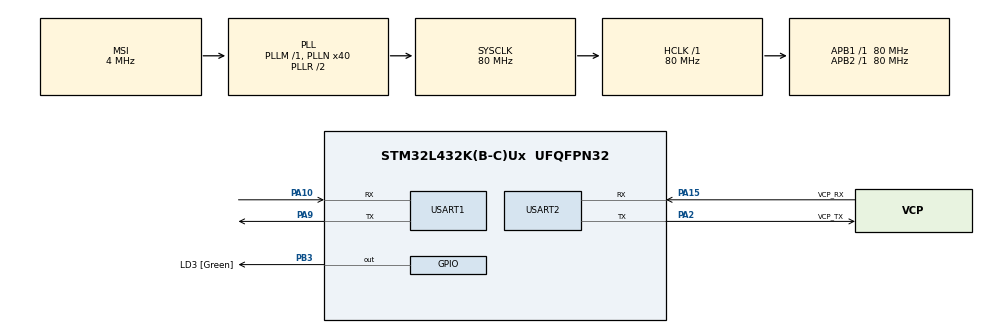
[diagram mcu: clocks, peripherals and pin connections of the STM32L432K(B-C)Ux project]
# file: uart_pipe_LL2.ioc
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Dma.Request0=USART1_RX
Dma.Request1=USART2_RX
Dma.USART1_RX.0.Direction=DMA_PERIPH_TO_MEMORY
Dma.USART1_RX.0.Instance=DMA1_Channel5
Dma.USART1_RX.0.MemDataAlignment=DMA_MDATAALIGN_BYTE
Dma.USART1_RX.0.MemInc=DMA_MINC_ENABLE
Dma.USART1_RX.0.Mode=DMA_NORMAL
Dma.USART1_RX.0.PeriphDataAlignment=DMA_PDATAALIGN_BYTE
Dma.USART1_RX.0.PeriphInc=DMA_PINC_DISABLE
Dma.USART1_RX.0.Priority=DMA_PRIORITY_HIGH
Dma.USART2_RX.1.Direction=DMA_PERIPH_TO_MEMORY
Dma.USART2_RX.1.Instance=DMA1_Channel6
Dma.USART2_RX.1.MemDataAlignment=DMA_MDATAALIGN_BYTE
Dma.USART2_RX.1.MemInc=DMA_MINC_ENABLE
Dma.USART2_RX.1.Mode=DMA_CIRCULAR
Dma.USART2_RX.1.PeriphDataAlignment=DMA_PDATAALIGN_BYTE
Dma.USART2_RX.1.PeriphInc=DMA_PINC_DISABLE
Dma.USART2_RX.1.Priority=DMA_PRIORITY_HIGH
Mcu.Family=STM32L4
Mcu.Name=STM32L432K(B-C)Ux
Mcu.Package=UFQFPN32
NVIC.DMA1_Channel5_IRQn=true\:0\:0\:false\:false\:true
NVIC.DMA1_Channel6_IRQn=true\:0\:0\:false\:false\:true
NVIC.PriorityGroup=NVIC_PRIORITYGROUP_4
NVIC.USART1_IRQn=true\:0\:0\:false\:false\:true
NVIC.USART2_IRQn=true\:0\:0\:true\:false\:true
PA0-CK_IN.GPIO_Label=MCO [High speed clock in]
PA0-CK_IN.Signal=RCC_CK_IN
PA10.Mode=Asynchronous
PA10.Signal=USART1_RX
PA13\ (JTMS-SWDIO).GPIO_Label=SWDIO
PA13\ (JTMS-SWDIO).Signal=SYS_JTMS-SWDIO
PA14\ (JTCK-SWCLK).GPIO_Label=SWCLK
PA14\ (JTCK-SWCLK).Signal=SYS_JTCK-SWCLK
PA15\ (JTDI).GPIO_Label=VCP_RX
PA15\ (JTDI).Mode=Asynchronous
PA15\ (JTDI).Signal=USART2_RX
PA2.GPIO_Label=VCP_TX
PA2.Mode=Asynchronous
PA2.Signal=USART2_TX
PA9.Mode=Asynchronous
PA9.Signal=USART1_TX
PB3\ (JTDO-TRACESWO).GPIO_Label=LD3 [Green]
PB3\ (JTDO-TRACESWO).Signal=GPIO_Output
PC14-OSC32_IN\ (PC14).Signal=RCC_OSC32_IN
PC15-OSC32_OUT\ (PC15).Signal=RCC_OSC32_OUT
ProjectManager.HeapSize=0x200
ProjectManager.StackSize=0x400
ProjectManager.TargetToolchain=SW4STM32
RCC.AHBFreq_Value=80000000
RCC.APB1Freq_Value=80000000
RCC.APB1TimFreq_Value=80000000
RCC.APB2Freq_Value=80000000
RCC.APB2TimFreq_Value=80000000
RCC.CortexFreq_Value=80000000
RCC.HCLKFreq_Value=80000000
RCC.HSE_VALUE=8000000
RCC.HSI16_VALUE=16000000
RCC.HSI48_VALUE=48000000
RCC.HSI_VALUE=16000000
RCC.LSE_VALUE=32768
RCC.MSI_VALUE=4000000
RCC.PLLMUL=RCC_PLLMUL_4
RCC.PLLN=40
RCC.SYSCLKFreq_VALUE=80000000
RCC.SYSCLKSource=RCC_SYSCLKSOURCE_PLLCLK
RCC.VCOOutputFreq_Value=160000000
USART1.WordLength=UART_WORDLENGTH_8B
USART2.WordLength=UART_WORDLENGTH_8B
board=NUCLEO-L432KC

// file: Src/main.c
/**
  ******************************************************************************
  * File Name          : main.c
  * Description        : Main program body
  ******************************************************************************
  *
  * COPYRIGHT(c) 2016 STMicroelectronics
  *
  * Redistribution and use in source and binary forms, with or without modification,
  * are permitted provided that the following conditions are met:
  *   1. Redistributions of source code must retain the above copyright notice,
  *      this list of conditions and the following disclaimer.
  *   2. Redistributions in binary form must reproduce the above copyright notice,
  *      this list of conditions and the following disclaimer in the documentation
  *      and/or other materials provided with the distribution.
  *   3. Neither the name of STMicroelectronics nor the names of its contributors
  *      may be used to endorse or promote products derived from this software
  *      without specific prior written permission.
  *
  * THIS SOFTWARE IS PROVIDED BY THE COPYRIGHT HOLDERS AND CONTRIBUTORS "AS IS"
  * AND ANY EXPRESS OR IMPLIED WARRANTIES, INCLUDING, BUT NOT LIMITED TO, THE
  * IMPLIED WARRANTIES OF MERCHANTABILITY AND FITNESS FOR A PARTICULAR PURPOSE ARE
  * DISCLAIMED. IN NO EVENT SHALL THE COPYRIGHT HOLDER OR CONTRIBUTORS BE LIABLE
  * FOR ANY DIRECT, INDIRECT, INCIDENTAL, SPECIAL, EXEMPLARY, OR CONSEQUENTIAL
  * DAMAGES (INCLUDING, BUT NOT LIMITED TO, PROCUREMENT OF SUBSTITUTE GOODS OR
  * SERVICES; LOSS OF USE, DATA, OR PROFITS; OR BUSINESS INTERRUPTION) HOWEVER
  * CAUSED AND ON ANY THEORY OF LIABILITY, WHETHER IN CONTRACT, STRICT LIABILITY,
  * OR TORT (INCLUDING NEGLIGENCE OR OTHERWISE) ARISING IN ANY WAY OUT OF THE USE
  * OF THIS SOFTWARE, EVEN IF ADVISED OF THE POSSIBILITY OF SUCH DAMAGE.
  *
  ******************************************************************************
  */
#include "main.h"
#include "stm32l4xx_hal.h"

/* USER CODE BEGIN Includes */

#include "serial.h"

/* USER CODE END Includes */

UART_HandleTypeDef huart1;
UART_HandleTypeDef huart2;
DMA_HandleTypeDef hdma_usart1_rx;
DMA_HandleTypeDef hdma_usart2_rx;

/* USER CODE BEGIN PV */
/* Private variables ---------------------------------------------------------*/

//UARTSerial_t Serial2;

/* USER CODE END PV */

void SystemClock_Config(void);
void Error_Handler(void);
static void MX_GPIO_Init(void);
static void MX_DMA_Init(void);
static void MX_USART1_UART_Init(void);
static void MX_USART2_UART_Init(void);

/* USER CODE BEGIN PFP */
/* Private function prototypes -----------------------------------------------*/

/* USER CODE END PFP */

int main(void)
{

  /* MCU Configuration----------------------------------------------------------*/

  /* Reset of all peripherals, Initializes the Flash interface and the Systick. */
  HAL_Init();

  /* Configure the system clock */
  SystemClock_Config();

  /* Initialize all configured peripherals */
  MX_GPIO_Init();
  MX_DMA_Init();
  MX_USART1_UART_Init();
  MX_USART2_UART_Init();

  /* USER CODE BEGIN 2 */

  Serial2_begin();

  /* USER CODE END 2 */

  /* Infinite loop */
  while (1)
  {
//	  if(Serial2_available()){
//		  Serial2_write(Serial2_read());
//	  }

	  if(Serial2_available()){
		  uint8_t lol[32]; //the buffer required for reading multiple bytes
		  int l = Serial2_readCommand(lol); //returns length of command
		  if(l>0){
			  //below check only needed if you're not sure if the bus will be free.
			  //use in a for loop for timeout, i guess. Should clear fast at 115200B/s.
			  while(Serial2_availableForWrite()==0);
			  Serial2_writeBytes(lol, l);
		  }
	  }

//	  if(Serial2_available()==2){
//		  uint8_t lol[2];
//		  Serial2_readBytes(lol,2);
//		  while(Serial2_availableForWrite()==0);
//		  Serial2_writeBytes(lol,2);
//	  }
  }

}

/** System Clock Configuration
*/
void SystemClock_Config(void)
{

  RCC_OscInitTypeDef RCC_OscInitStruct;
  RCC_ClkInitTypeDef RCC_ClkInitStruct;
  RCC_PeriphCLKInitTypeDef PeriphClkInit;

    /**Initializes the CPU, AHB and APB busses clocks
    */
  RCC_OscInitStruct.OscillatorType = RCC_OSCILLATORTYPE_MSI;
  RCC_OscInitStruct.MSIState = RCC_MSI_ON;
  RCC_OscInitStruct.MSICalibrationValue = 0;
  RCC_OscInitStruct.MSIClockRange = RCC_MSIRANGE_6;
  RCC_OscInitStruct.PLL.PLLState = RCC_PLL_ON;
  RCC_OscInitStruct.PLL.PLLSource = RCC_PLLSOURCE_MSI;
  RCC_OscInitStruct.PLL.PLLM = 1;
  RCC_OscInitStruct.PLL.PLLN = 40;
  RCC_OscInitStruct.PLL.PLLP = RCC_PLLP_DIV7;
  RCC_OscInitStruct.PLL.PLLQ = RCC_PLLQ_DIV2;
  RCC_OscInitStruct.PLL.PLLR = RCC_PLLR_DIV2;
  if (HAL_RCC_OscConfig(&RCC_OscInitStruct) != HAL_OK)
  {
    Error_Handler();
  }

    /**Initializes the CPU, AHB and APB busses clocks
    */
  RCC_ClkInitStruct.ClockType = RCC_CLOCKTYPE_HCLK|RCC_CLOCKTYPE_SYSCLK
                              |RCC_CLOCKTYPE_PCLK1|RCC_CLOCKTYPE_PCLK2;
  RCC_ClkInitStruct.SYSCLKSource = RCC_SYSCLKSOURCE_PLLCLK;
  RCC_ClkInitStruct.AHBCLKDivider = RCC_SYSCLK_DIV1;
  RCC_ClkInitStruct.APB1CLKDivider = RCC_HCLK_DIV1;
  RCC_ClkInitStruct.APB2CLKDivider = RCC_HCLK_DIV1;

  if (HAL_RCC_ClockConfig(&RCC_ClkInitStruct, FLASH_LATENCY_4) != HAL_OK)
  {
    Error_Handler();
  }

  PeriphClkInit.PeriphClockSelection = RCC_PERIPHCLK_USART1|RCC_PERIPHCLK_USART2;
  PeriphClkInit.Usart1ClockSelection = RCC_USART1CLKSOURCE_PCLK2;
  PeriphClkInit.Usart2ClockSelection = RCC_USART2CLKSOURCE_PCLK1;
  if (HAL_RCCEx_PeriphCLKConfig(&PeriphClkInit) != HAL_OK)
  {
    Error_Handler();
  }

    /**Configure the main internal regulator output voltage
    */
  if (HAL_PWREx_ControlVoltageScaling(PWR_REGULATOR_VOLTAGE_SCALE1) != HAL_OK)
  {
    Error_Handler();
  }

    /**Configure the Systick interrupt time
    */
  HAL_SYSTICK_Config(HAL_RCC_GetHCLKFreq()/1000);

    /**Configure the Systick
    */
  HAL_SYSTICK_CLKSourceConfig(SYSTICK_CLKSOURCE_HCLK);

  /* SysTick_IRQn interrupt configuration */
  HAL_NVIC_SetPriority(SysTick_IRQn, 0, 0);
}

/* USART1 init function */
static void MX_USART1_UART_Init(void)
{

  huart1.Instance = USART1;
  huart1.Init.BaudRate = 115200;
  huart1.Init.WordLength = UART_WORDLENGTH_8B;
  huart1.Init.StopBits = UART_STOPBITS_1;
  huart1.Init.Parity = UART_PARITY_NONE;
  huart1.Init.Mode = UART_MODE_TX_RX;
  huart1.Init.HwFlowCtl = UART_HWCONTROL_NONE;
  huart1.Init.OverSampling = UART_OVERSAMPLING_16;
  huart1.Init.OneBitSampling = UART_ONE_BIT_SAMPLE_DISABLE;
  huart1.AdvancedInit.AdvFeatureInit = UART_ADVFEATURE_NO_INIT;
  if (HAL_UART_Init(&huart1) != HAL_OK)
  {
    Error_Handler();
  }

}

/* USART2 init function */
static void MX_USART2_UART_Init(void)
{

  huart2.Instance = USART2;
  huart2.Init.BaudRate = 115200;
  huart2.Init.WordLength = UART_WORDLENGTH_8B;
  huart2.Init.StopBits = UART_STOPBITS_1;
  huart2.Init.Parity = UART_PARITY_NONE;
  huart2.Init.Mode = UART_MODE_TX_RX;
  huart2.Init.HwFlowCtl = UART_HWCONTROL_NONE;
  huart2.Init.OverSampling = UART_OVERSAMPLING_16;
  huart2.Init.OneBitSampling = UART_ONE_BIT_SAMPLE_DISABLE;
  huart2.AdvancedInit.AdvFeatureInit = UART_ADVFEATURE_NO_INIT;
  if (HAL_UART_Init(&huart2) != HAL_OK)
  {
    Error_Handler();
  }

}

static void MX_DMA_Init(void)
{
  /* DMA controller clock enable */
  LL_AHB1_GRP1_EnableClock(LL_AHB1_GRP1_PERIPH_DMA1);

  /* DMA interrupt init */
  /* DMA1_Channel5_IRQn interrupt configuration */
  HAL_NVIC_SetPriority(DMA1_Channel5_IRQn, 0, 0);
  HAL_NVIC_EnableIRQ(DMA1_Channel5_IRQn);
  /* DMA1_Channel6_IRQn interrupt configuration */
  HAL_NVIC_SetPriority(DMA1_Channel6_IRQn, 0, 0);
  HAL_NVIC_EnableIRQ(DMA1_Channel6_IRQn);

}

/** Configure pins as
        * Analog
        * Input
        * Output
        * EVENT_OUT
        * EXTI
*/
static void MX_GPIO_Init(void)
{

  GPIO_InitTypeDef GPIO_InitStruct;

  /* GPIO Ports Clock Enable */
  __HAL_RCC_GPIOC_CLK_ENABLE();
  __HAL_RCC_GPIOA_CLK_ENABLE();
  __HAL_RCC_GPIOB_CLK_ENABLE();

  /*Configure GPIO pin Output Level */
  HAL_GPIO_WritePin(LD3_GPIO_Port, LD3_Pin, GPIO_PIN_RESET);

  /*Configure GPIO pin : LD3_Pin */
  GPIO_InitStruct.Pin = LD3_Pin;
  GPIO_InitStruct.Mode = GPIO_MODE_OUTPUT_PP;
  GPIO_InitStruct.Pull = GPIO_NOPULL;
  GPIO_InitStruct.Speed = GPIO_SPEED_FREQ_LOW;
  HAL_GPIO_Init(LD3_GPIO_Port, &GPIO_InitStruct);

}

void Error_Handler(void)
{
  while(1)
  {
  }
}

/************************ (C) COPYRIGHT STMicroelectronics *****END OF FILE****/
